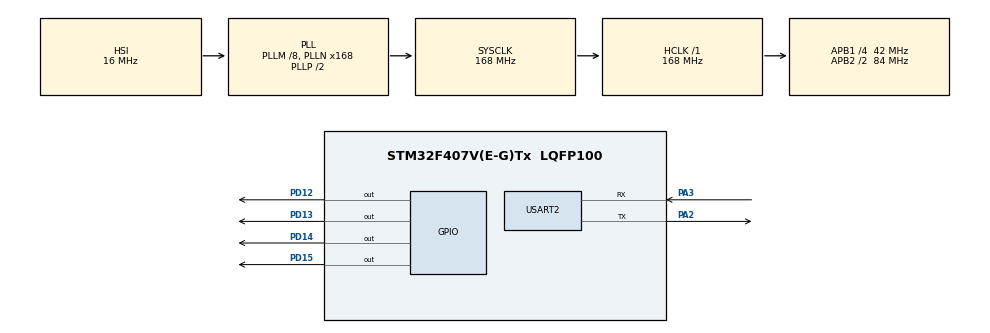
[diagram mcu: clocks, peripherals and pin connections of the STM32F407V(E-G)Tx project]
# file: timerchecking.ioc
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FREERTOS.Tasks01=defaultTask,0,128,StartDefaultTask,Default;myTask02,0,128,StartTask02,Default
FREERTOS.Timers01=myTimer01,Callback01,osTimerOnce,Default
FREERTOS.configTIMER_QUEUE_LENGTH=16
FREERTOS.configTIMER_TASK_PRIORITY=1
FREERTOS.configUSE_TIMERS=1
Mcu.Family=STM32F4
Mcu.Name=STM32F407V(E-G)Tx
Mcu.Package=LQFP100
NVIC.PriorityGroup=NVIC_PRIORITYGROUP_4
NVIC.TIM1_UP_TIM10_IRQn=true\:0\:0\:false\:false\:true\:false
NVIC.TimeBase=TIM1_UP_TIM10_IRQn
NVIC.TimeBaseIP=TIM1
NVIC.USART2_IRQn=true\:0\:0\:false\:false\:true\:false
PA13.Mode=Serial_Wire
PA13.Signal=SYS_JTMS-SWDIO
PA14.Mode=Serial_Wire
PA14.Signal=SYS_JTCK-SWCLK
PA2.Mode=Asynchronous
PA2.Signal=USART2_TX
PA3.Mode=Asynchronous
PA3.Signal=USART2_RX
PC14-OSC32_IN.Mode=LSE-External-Oscillator
PC14-OSC32_IN.Signal=RCC_OSC32_IN
PC15-OSC32_OUT.Mode=LSE-External-Oscillator
PC15-OSC32_OUT.Signal=RCC_OSC32_OUT
PD12.Signal=GPIO_Output
PD13.Signal=GPIO_Output
PD14.Signal=GPIO_Output
PD15.Signal=GPIO_Output
PH0-OSC_IN.Mode=HSE-External-Oscillator
PH0-OSC_IN.Signal=RCC_OSC_IN
PH1-OSC_OUT.Mode=HSE-External-Oscillator
PH1-OSC_OUT.Signal=RCC_OSC_OUT
ProjectManager.HeapSize=0x200
ProjectManager.StackSize=0x400
ProjectManager.TargetToolchain=MDK-ARM V5
RCC.48MHZClocksFreq_Value=84000000
RCC.AHBFreq_Value=168000000
RCC.APB1CLKDivider=RCC_HCLK_DIV4
RCC.APB1Freq_Value=42000000
RCC.APB1TimFreq_Value=84000000
RCC.APB2CLKDivider=RCC_HCLK_DIV2
RCC.APB2Freq_Value=84000000
RCC.APB2TimFreq_Value=168000000
RCC.CortexFreq_Value=168000000
RCC.HCLKFreq_Value=168000000
RCC.HSE_VALUE=25000000
RCC.HSI_VALUE=16000000
RCC.PLLM=8
RCC.PLLN=168
RCC.SYSCLKFreq_VALUE=168000000
RCC.SYSCLKSource=RCC_SYSCLKSOURCE_PLLCLK
RCC.VCOOutputFreq_Value=336000000
VP_FREERTOS_VS_ENABLE.Mode=Enabled
VP_SYS_VS_tim1.Mode=TIM1
board=timerchecking

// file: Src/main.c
/**
  ******************************************************************************
  * File Name          : main.c
  * Description        : Main program body
  ******************************************************************************
  *
  * COPYRIGHT(c) 2017 STMicroelectronics
  *
  * Redistribution and use in source and binary forms, with or without modification,
  * are permitted provided that the following conditions are met:
  *   1. Redistributions of source code must retain the above copyright notice,
  *      this list of conditions and the following disclaimer.
  *   2. Redistributions in binary form must reproduce the above copyright notice,
  *      this list of conditions and the following disclaimer in the documentation
  *      and/or other materials provided with the distribution.
  *   3. Neither the name of STMicroelectronics nor the names of its contributors
  *      may be used to endorse or promote products derived from this software
  *      without specific prior written permission.
  *
  * THIS SOFTWARE IS PROVIDED BY THE COPYRIGHT HOLDERS AND CONTRIBUTORS "AS IS"
  * AND ANY EXPRESS OR IMPLIED WARRANTIES, INCLUDING, BUT NOT LIMITED TO, THE
  * IMPLIED WARRANTIES OF MERCHANTABILITY AND FITNESS FOR A PARTICULAR PURPOSE ARE
  * DISCLAIMED. IN NO EVENT SHALL THE COPYRIGHT HOLDER OR CONTRIBUTORS BE LIABLE
  * FOR ANY DIRECT, INDIRECT, INCIDENTAL, SPECIAL, EXEMPLARY, OR CONSEQUENTIAL
  * DAMAGES (INCLUDING, BUT NOT LIMITED TO, PROCUREMENT OF SUBSTITUTE GOODS OR
  * SERVICES; LOSS OF USE, DATA, OR PROFITS; OR BUSINESS INTERRUPTION) HOWEVER
  * CAUSED AND ON ANY THEORY OF LIABILITY, WHETHER IN CONTRACT, STRICT LIABILITY,
  * OR TORT (INCLUDING NEGLIGENCE OR OTHERWISE) ARISING IN ANY WAY OUT OF THE USE
  * OF THIS SOFTWARE, EVEN IF ADVISED OF THE POSSIBILITY OF SUCH DAMAGE.
  *
  ******************************************************************************
  */
#include "stm32f4xx_hal.h"
#include "cmsis_os.h"
#include "eeprom.h"
int i=0;

UART_HandleTypeDef huart2;

osThreadId defaultTaskHandle;
osThreadId myTask02Handle;
osTimerId myTimer01Handle;

/* USER CODE BEGIN PV */
/* Private variables ---------------------------------------------------------*/

/* USER CODE END PV */

void SystemClock_Config(void);
void Error_Handler(void);
static void MX_GPIO_Init(void);
static void MX_USART2_UART_Init(void);
void StartDefaultTask(void const * argument);
void StartTask02(void const * argument);
void Callback01(void const * argument);
uint16_t VirtAddVarTab[1] = {0x5555};
uint16_t VarDataTab[1];
uint16_t VarValue,VarDataTmp = 0;
/* USER CODE BEGIN PFP */
/* Private function prototypes -----------------------------------------------*/

/* USER CODE END PFP */

int main(void)
{

  /* MCU Configuration----------------------------------------------------------*/

  /* Reset of all peripherals, Initializes the Flash interface and the Systick. */
  HAL_Init();

	 HAL_FLASH_Unlock();

  /* Configure the system clock */
  SystemClock_Config();

  /* Initialize all configured peripherals */
  MX_GPIO_Init();
  MX_USART2_UART_Init();
	if(EE_Init()!=HAL_OK)
	{
    Error_Handler();
	}

  /* Create the timer(s) */
  /* definition and creation of myTimer01 */
  osTimerDef(myTimer01, Callback01);
  myTimer01Handle = osTimerCreate(osTimer(myTimer01), osTimerOnce, NULL);

  /* Create the thread(s) */
  /* definition and creation of defaultTask */
  osThreadDef(defaultTask, StartDefaultTask, osPriorityNormal, 0, 128);
  defaultTaskHandle = osThreadCreate(osThread(defaultTask), NULL);

  /* definition and creation of myTask02 */
  osThreadDef(myTask02, StartTask02, osPriorityNormal, 0, 128);
  myTask02Handle = osThreadCreate(osThread(myTask02), NULL);

  /* Start scheduler */
  osKernelStart();

  /* We should never get here as control is now taken by the scheduler */

  /* Infinite loop */
  while (1)
  {

  }

}

/** System Clock Configuration
*/
void SystemClock_Config(void)
{

  RCC_OscInitTypeDef RCC_OscInitStruct;
  RCC_ClkInitTypeDef RCC_ClkInitStruct;

  __HAL_RCC_PWR_CLK_ENABLE();

  __HAL_PWR_VOLTAGESCALING_CONFIG(PWR_REGULATOR_VOLTAGE_SCALE1);

  RCC_OscInitStruct.OscillatorType = RCC_OSCILLATORTYPE_HSI;
  RCC_OscInitStruct.HSIState = RCC_HSI_ON;
  RCC_OscInitStruct.HSICalibrationValue = 16;
  RCC_OscInitStruct.PLL.PLLState = RCC_PLL_ON;
  RCC_OscInitStruct.PLL.PLLSource = RCC_PLLSOURCE_HSI;
  RCC_OscInitStruct.PLL.PLLM = 8;
  RCC_OscInitStruct.PLL.PLLN = 168;
  RCC_OscInitStruct.PLL.PLLP = RCC_PLLP_DIV2;
  RCC_OscInitStruct.PLL.PLLQ = 4;
  if (HAL_RCC_OscConfig(&RCC_OscInitStruct) != HAL_OK)
  {
    Error_Handler();
  }

  RCC_ClkInitStruct.ClockType = RCC_CLOCKTYPE_HCLK|RCC_CLOCKTYPE_SYSCLK
                              |RCC_CLOCKTYPE_PCLK1|RCC_CLOCKTYPE_PCLK2;
  RCC_ClkInitStruct.SYSCLKSource = RCC_SYSCLKSOURCE_PLLCLK;
  RCC_ClkInitStruct.AHBCLKDivider = RCC_SYSCLK_DIV1;
  RCC_ClkInitStruct.APB1CLKDivider = RCC_HCLK_DIV4;
  RCC_ClkInitStruct.APB2CLKDivider = RCC_HCLK_DIV2;
  if (HAL_RCC_ClockConfig(&RCC_ClkInitStruct, FLASH_LATENCY_5) != HAL_OK)
  {
    Error_Handler();
  }

  HAL_SYSTICK_Config(HAL_RCC_GetHCLKFreq()/1000);

  HAL_SYSTICK_CLKSourceConfig(SYSTICK_CLKSOURCE_HCLK);

  /* SysTick_IRQn interrupt configuration */
  HAL_NVIC_SetPriority(SysTick_IRQn, 15, 0);
}

/* USART2 init function */
static void MX_USART2_UART_Init(void)
{

  huart2.Instance = USART2;
  huart2.Init.BaudRate = 115200;
  huart2.Init.WordLength = UART_WORDLENGTH_8B;
  huart2.Init.StopBits = UART_STOPBITS_1;
  huart2.Init.Parity = UART_PARITY_NONE;
  huart2.Init.Mode = UART_MODE_TX_RX;
  huart2.Init.HwFlowCtl = UART_HWCONTROL_NONE;
  huart2.Init.OverSampling = UART_OVERSAMPLING_16;
  if (HAL_UART_Init(&huart2) != HAL_OK)
  {
    Error_Handler();
  }

}

/** Configure pins as
        * Analog
        * Input
        * Output
        * EVENT_OUT
        * EXTI
*/
static void MX_GPIO_Init(void)
{

  GPIO_InitTypeDef GPIO_InitStruct;

  /* GPIO Ports Clock Enable */
  __HAL_RCC_GPIOC_CLK_ENABLE();
  __HAL_RCC_GPIOH_CLK_ENABLE();
  __HAL_RCC_GPIOA_CLK_ENABLE();
  __HAL_RCC_GPIOD_CLK_ENABLE();

  /*Configure GPIO pin Output Level */
  HAL_GPIO_WritePin(GPIOD, GPIO_PIN_12|GPIO_PIN_13|GPIO_PIN_14|GPIO_PIN_15, GPIO_PIN_RESET);

  /*Configure GPIO pins : PD12 PD13 PD14 PD15 */
  GPIO_InitStruct.Pin = GPIO_PIN_12|GPIO_PIN_13|GPIO_PIN_14|GPIO_PIN_15;
  GPIO_InitStruct.Mode = GPIO_MODE_OUTPUT_PP;
  GPIO_InitStruct.Pull = GPIO_NOPULL;
  GPIO_InitStruct.Speed = GPIO_SPEED_FREQ_LOW;
  HAL_GPIO_Init(GPIOD, &GPIO_InitStruct);

}

/* StartDefaultTask function */
void StartDefaultTask(void const * argument)
{

  for(;;)
  {
    osDelay(1);
  }
}

/* StartTask02 function */
void StartTask02(void const * argument)
{
  /* USER CODE BEGIN StartTask02 */
  /* Infinite loop */
	i=0;
  for(;;)
  {
				if(!i){
					osTimerStart (myTimer01Handle,5000);
					i=1;
					HAL_GPIO_TogglePin(GPIOD,GPIO_PIN_14);
					HAL_UART_Transmit(&huart2 , (uint8_t *)"first time\n", 12, 50);

				}

			else
			{
				HAL_GPIO_TogglePin(GPIOD,GPIO_PIN_12);
				HAL_UART_Transmit(&huart2 , (uint8_t *)"second time\n", 14, 50);
				osDelay(2500);
			}

  }
  /* USER CODE END StartTask02 */
}

/* Callback01 function */
void Callback01(void const * argument)
{
  /* USER CODE BEGIN Callback01 */
  HAL_GPIO_TogglePin(GPIOD,GPIO_PIN_13);
	HAL_UART_Transmit(&huart2, (uint8_t *)"LAPSED\n", 8, 50);
	i=0;
  /* USER CODE END Callback01 */
}

void HAL_TIM_PeriodElapsedCallback(TIM_HandleTypeDef *htim)
{
  if (htim->Instance == TIM1) {
    HAL_IncTick();
  }
}

void Error_Handler(void)
{
  while(1)
  {
  }
}

/************************ (C) COPYRIGHT STMicroelectronics *****END OF FILE****/
